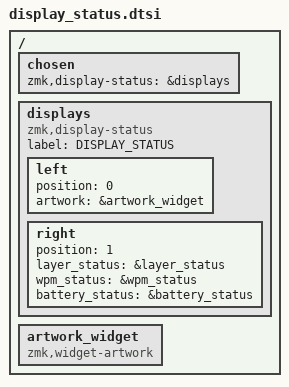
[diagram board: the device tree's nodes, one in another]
#include <dt-bindings/zmk/display.h>

/ {
    chosen {
        zmk,display-status = &displays;
    };

    displays {
        compatible = "zmk,display-status";
        label = "DISPLAY_STATUS";

        // Left display with custom artwork
        left {
            position = <0>;
            artwork = &artwork_widget;
        };

        // Right display with default widgets
        right {
            position = <1>;
            layer_status = &layer_status;
            wpm_status = &wpm_status;
            battery_status = &battery_status;
        };
    };

    artwork_widget: artwork_widget {
        compatible = "zmk,widget-artwork";
    };
};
